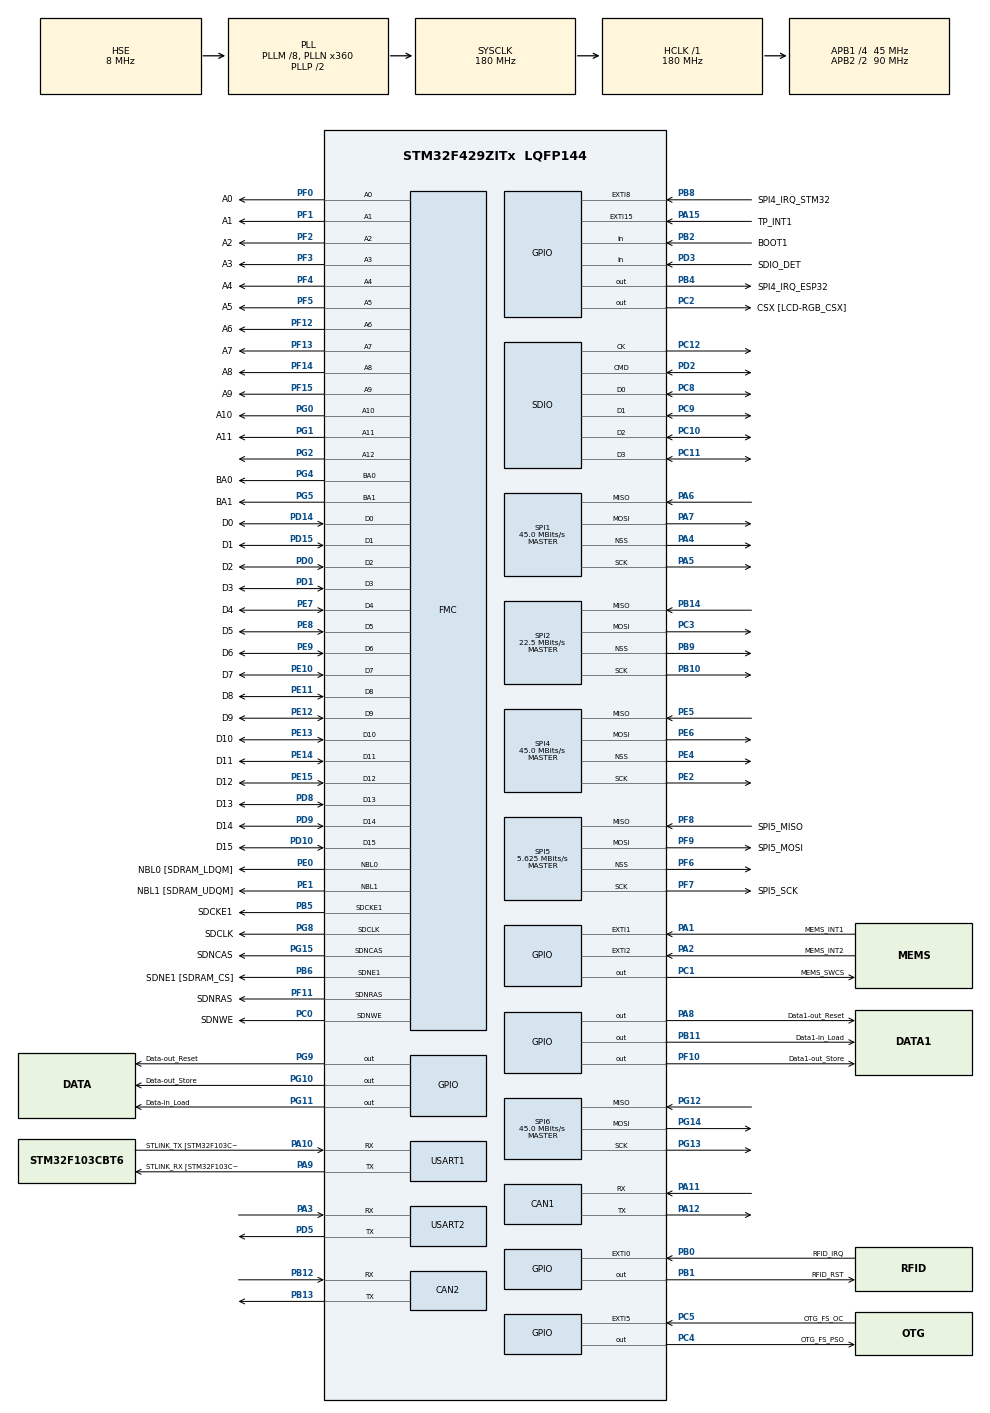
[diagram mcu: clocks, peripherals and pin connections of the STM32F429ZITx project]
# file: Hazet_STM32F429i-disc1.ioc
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CAN1.BS1=CAN_BS1_1TQ
CAN1.BS2=CAN_BS2_1TQ
CAN1.CalculateTimeQuantum=355.55555555555554
CAN2.BS1=CAN_BS1_1TQ
CAN2.BS2=CAN_BS2_1TQ
CAN2.CalculateTimeQuantum=355.55555555555554
Dma.Request0=SPI5_TX
Dma.Request1=USART2_TX
Dma.Request2=SDIO_RX
Dma.Request3=SDIO_TX
Dma.SDIO_RX.2.Direction=DMA_PERIPH_TO_MEMORY
Dma.SDIO_RX.2.FIFOMode=DMA_FIFOMODE_ENABLE
Dma.SDIO_RX.2.FIFOThreshold=DMA_FIFO_THRESHOLD_FULL
Dma.SDIO_RX.2.Instance=DMA2_Stream3
Dma.SDIO_RX.2.MemBurst=DMA_MBURST_INC4
Dma.SDIO_RX.2.MemDataAlignment=DMA_MDATAALIGN_WORD
Dma.SDIO_RX.2.MemInc=DMA_MINC_ENABLE
Dma.SDIO_RX.2.Mode=DMA_PFCTRL
Dma.SDIO_RX.2.PeriphBurst=DMA_PBURST_INC4
Dma.SDIO_RX.2.PeriphDataAlignment=DMA_PDATAALIGN_WORD
Dma.SDIO_RX.2.PeriphInc=DMA_PINC_DISABLE
Dma.SDIO_RX.2.Priority=DMA_PRIORITY_LOW
Dma.SDIO_TX.3.Direction=DMA_MEMORY_TO_PERIPH
Dma.SDIO_TX.3.FIFOMode=DMA_FIFOMODE_ENABLE
Dma.SDIO_TX.3.FIFOThreshold=DMA_FIFO_THRESHOLD_FULL
Dma.SDIO_TX.3.Instance=DMA2_Stream6
Dma.SDIO_TX.3.MemBurst=DMA_MBURST_INC4
Dma.SDIO_TX.3.MemDataAlignment=DMA_MDATAALIGN_WORD
Dma.SDIO_TX.3.MemInc=DMA_MINC_ENABLE
Dma.SDIO_TX.3.Mode=DMA_PFCTRL
Dma.SDIO_TX.3.PeriphBurst=DMA_PBURST_INC4
Dma.SDIO_TX.3.PeriphDataAlignment=DMA_PDATAALIGN_WORD
Dma.SDIO_TX.3.PeriphInc=DMA_PINC_DISABLE
Dma.SDIO_TX.3.Priority=DMA_PRIORITY_LOW
Dma.SPI5_TX.0.Direction=DMA_MEMORY_TO_PERIPH
Dma.SPI5_TX.0.FIFOMode=DMA_FIFOMODE_DISABLE
Dma.SPI5_TX.0.Instance=DMA2_Stream4
Dma.SPI5_TX.0.MemDataAlignment=DMA_MDATAALIGN_BYTE
Dma.SPI5_TX.0.MemInc=DMA_MINC_ENABLE
Dma.SPI5_TX.0.Mode=DMA_NORMAL
Dma.SPI5_TX.0.PeriphDataAlignment=DMA_PDATAALIGN_BYTE
Dma.SPI5_TX.0.PeriphInc=DMA_PINC_DISABLE
Dma.SPI5_TX.0.Priority=DMA_PRIORITY_LOW
Dma.USART2_TX.1.Direction=DMA_MEMORY_TO_PERIPH
Dma.USART2_TX.1.FIFOMode=DMA_FIFOMODE_DISABLE
Dma.USART2_TX.1.Instance=DMA1_Stream6
Dma.USART2_TX.1.MemDataAlignment=DMA_MDATAALIGN_BYTE
Dma.USART2_TX.1.MemInc=DMA_MINC_ENABLE
Dma.USART2_TX.1.Mode=DMA_NORMAL
Dma.USART2_TX.1.PeriphDataAlignment=DMA_PDATAALIGN_BYTE
Dma.USART2_TX.1.PeriphInc=DMA_PINC_DISABLE
Dma.USART2_TX.1.Priority=DMA_PRIORITY_LOW
FATFS.BSP.number=1
FATFS.USE_DMA_CODE_SD=1
FATFS0.BSP.STBoard=false
FATFS0.BSP.api=Unknown
FATFS0.BSP.i2caddr=0
FATFS0.BSP.instance=PD3
FATFS0.BSP.ip=GPIO
FATFS0.BSP.mode=Input
FATFS0.BSP.name=Detect_SDIO
FATFS0.BSP.solution=PD3
FMC.CASLatency1=FMC_SDRAM_CAS_LATENCY_3
FMC.ExitSelfRefreshDelay1=7
FMC.LoadToActiveDelay1=2
FMC.RCDDelay1=2
FMC.RPDelay1=2
FMC.ReadBurst1=FMC_SDRAM_RBURST_DISABLE
FMC.ReadPipeDelay1=FMC_SDRAM_RPIPE_DELAY_1
FMC.RowCycleDelay1=7
FMC.SDClockPeriod1=FMC_SDRAM_CLOCK_PERIOD_2
FMC.SelfRefreshTime1=4
FMC.WriteRecoveryTime1=3
Mcu.Family=STM32F4
Mcu.Name=STM32F429ZITx
Mcu.Package=LQFP144
NVIC.DMA1_Stream6_IRQn=true\:0\:0\:false\:false\:true\:false\:true
NVIC.DMA2_Stream3_IRQn=true\:0\:0\:false\:false\:true\:false\:true
NVIC.DMA2_Stream4_IRQn=true\:0\:0\:false\:false\:true\:false\:true
NVIC.DMA2_Stream6_IRQn=true\:0\:0\:false\:false\:true\:false\:true
NVIC.PriorityGroup=NVIC_PRIORITYGROUP_4
NVIC.SDIO_IRQn=true\:0\:0\:false\:false\:true\:true\:true
NVIC.SPI5_IRQn=true\:0\:0\:false\:false\:true\:true\:true
NVIC.TIM6_DAC_IRQn=true\:0\:0\:false\:false\:true\:false\:true
NVIC.TimeBase=TIM6_DAC_IRQn
NVIC.TimeBaseIP=TIM6
NVIC.USART2_IRQn=true\:0\:0\:false\:false\:true\:true\:true
PA1.GPIO_Label=MEMS_INT1
PA1.GPIO_ModeDefaultEXTI=GPIO_MODE_EVT_RISING
PA1.GPIO_PuPd=GPIO_NOPULL
PA1.Signal=GPXTI1
PA10.GPIO_Label=STLINK_TX [STM32F103CBT6_PA2]
PA10.Mode=Asynchronous
PA10.Signal=USART1_RX
PA11.Mode=Master
PA11.Signal=CAN1_RX
PA12.Mode=Master
PA12.Signal=CAN1_TX
PA13.GPIO_Label=SWDIO
PA13.Mode=Trace_Asynchronous_SW
PA13.Signal=SYS_JTMS-SWDIO
PA14.GPIO_Label=SWCLK
PA14.Mode=Trace_Asynchronous_SW
PA14.Signal=SYS_JTCK-SWCLK
PA15.GPIO_Label=TP_INT1
PA15.GPIO_ModeDefaultEXTI=GPIO_MODE_EVT_RISING
PA15.GPIO_PuPd=GPIO_NOPULL
PA15.Signal=GPXTI15
PA2.GPIO_Label=MEMS_INT2
PA2.GPIO_ModeDefaultEXTI=GPIO_MODE_EVT_RISING
PA2.GPIO_PuPd=GPIO_NOPULL
PA2.Signal=GPXTI2
PA3.Mode=Asynchronous
PA3.Signal=USART2_RX
PA4.Mode=NSS_Signal_Hard_Output
PA4.Signal=SPI1_NSS
PA5.Mode=Full_Duplex_Master
PA5.Signal=SPI1_SCK
PA6.Mode=Full_Duplex_Master
PA6.Signal=SPI1_MISO
PA7.Mode=Full_Duplex_Master
PA7.Signal=SPI1_MOSI
PA8.GPIO_Label=Data1-out_Reset
PA8.Signal=GPIO_Output
PA9.GPIO_Label=STLINK_RX [STM32F103CBT6_PA3]
PA9.Mode=Asynchronous
PA9.Signal=USART1_TX
PB0.GPIO_Label=RFID_IRQ
PB0.Signal=GPXTI0
PB1.GPIO_Label=RFID_RST
PB1.Signal=GPIO_Output
PB10.Mode=Full_Duplex_Master
PB10.Signal=SPI2_SCK
PB11.GPIO_Label=Data1-in_Load
PB11.Signal=GPIO_Output
PB12.Mode=Slave
PB12.Signal=CAN2_RX
PB13.Mode=Slave
PB13.Signal=CAN2_TX
PB14.Mode=Full_Duplex_Master
PB14.Signal=SPI2_MISO
PB2/BOOT1.GPIO_Label=BOOT1
PB2/BOOT1.GPIO_Mode=GPIO_MODE_INPUT
PB2/BOOT1.GPIO_PuPd=GPIO_NOPULL
PB2/BOOT1.Signal=GPIO_Input
PB3.GPIO_Label=SWO
PB3.Mode=Trace_Asynchronous_SW
PB3.Signal=SYS_JTDO-SWO
PB4.GPIO_Label=SPI4_IRQ_ESP32
PB4.Signal=GPIO_Output
PB5.GPIO_Label=SDCKE1
PB5.GPIO_Mode=GPIO_MODE_AF_PP
PB5.GPIO_PuPd=GPIO_NOPULL
PB5.GPIO_Speed=GPIO_SPEED_FREQ_VERY_HIGH
PB5.Mode=SdramChipSelect2_1
PB5.Signal=FMC_SDCKE1
PB6.GPIO_Label=SDNE1 [SDRAM_CS]
PB6.GPIO_Mode=GPIO_MODE_AF_PP
PB6.GPIO_PuPd=GPIO_NOPULL
PB6.GPIO_Speed=GPIO_SPEED_FREQ_VERY_HIGH
PB6.Mode=SdramChipSelect2_1
PB6.Signal=FMC_SDNE1
PB8.GPIO_Label=SPI4_IRQ_STM32
PB8.Signal=GPXTI8
PB9.Mode=NSS_Signal_Hard_Output
PB9.Signal=SPI2_NSS
PC0.GPIO_Label=SDNWE
PC0.GPIO_Mode=GPIO_MODE_AF_PP
PC0.GPIO_PuPd=GPIO_NOPULL
PC0.GPIO_Speed=GPIO_SPEED_FREQ_VERY_HIGH
PC0.Signal=FMC_SDNWE
PC1.GPIO_Label=MEMS_SWCS
PC1.GPIO_Mode=GPIO_MODE_OUTPUT_PP
PC1.GPIO_PuPd=GPIO_NOPULL
PC1.GPIO_Speed=GPIO_SPEED_FREQ_LOW
PC1.Signal=GPIO_Output
PC10.Mode=SD_4_bits_Wide_bus
PC10.Signal=SDIO_D2
PC11.Mode=SD_4_bits_Wide_bus
PC11.Signal=SDIO_D3
PC12.Mode=SD_4_bits_Wide_bus
PC12.Signal=SDIO_CK
PC2.GPIO_Label=CSX [LCD-RGB_CSX]
PC2.GPIO_Mode=GPIO_MODE_OUTPUT_PP
PC2.GPIO_PuPd=GPIO_NOPULL
PC2.GPIO_Speed=GPIO_SPEED_FREQ_LOW
PC2.Signal=GPIO_Output
PC3.Mode=Full_Duplex_Master
PC3.Signal=SPI2_MOSI
PC4.GPIO_Label=OTG_FS_PSO
PC4.GPIO_Mode=GPIO_MODE_OUTPUT_PP
PC4.GPIO_PuPd=GPIO_NOPULL
PC4.GPIO_Speed=GPIO_SPEED_FREQ_LOW
PC4.Signal=GPIO_Output
PC5.GPIO_Label=OTG_FS_OC
PC5.GPIO_ModeDefaultEXTI=GPIO_MODE_EVT_RISING
PC5.Signal=GPXTI5
PC8.Mode=SD_4_bits_Wide_bus
PC8.Signal=SDIO_D0
PC9.Mode=SD_4_bits_Wide_bus
PC9.Signal=SDIO_D1
PD0.GPIO_Label=D2
PD0.GPIO_Mode=GPIO_MODE_AF_PP
PD0.GPIO_PuPd=GPIO_NOPULL
PD0.GPIO_Speed=GPIO_SPEED_FREQ_VERY_HIGH
PD0.Signal=FMC_D2_DA2
PD1.GPIO_Label=D3
PD1.GPIO_Mode=GPIO_MODE_AF_PP
PD1.GPIO_PuPd=GPIO_NOPULL
PD1.GPIO_Speed=GPIO_SPEED_FREQ_VERY_HIGH
PD1.Signal=FMC_D3_DA3
PD10.GPIO_Label=D15
PD10.GPIO_Mode=GPIO_MODE_AF_PP
PD10.GPIO_PuPd=GPIO_NOPULL
PD10.GPIO_Speed=GPIO_SPEED_FREQ_VERY_HIGH
PD10.Signal=FMC_D15_DA15
PD14.GPIO_Label=D0
PD14.GPIO_Mode=GPIO_MODE_AF_PP
PD14.GPIO_PuPd=GPIO_NOPULL
PD14.GPIO_Speed=GPIO_SPEED_FREQ_VERY_HIGH
PD14.Signal=FMC_D0_DA0
PD15.GPIO_Label=D1
PD15.GPIO_Mode=GPIO_MODE_AF_PP
PD15.GPIO_PuPd=GPIO_NOPULL
PD15.GPIO_Speed=GPIO_SPEED_FREQ_VERY_HIGH
PD15.Signal=FMC_D1_DA1
PD2.Mode=SD_4_bits_Wide_bus
PD2.Signal=SDIO_CMD
PD3.GPIO_Label=SDIO_DET
PD3.Signal=GPIO_Input
PD5.Mode=Asynchronous
PD5.Signal=USART2_TX
PD8.GPIO_Label=D13
PD8.GPIO_Mode=GPIO_MODE_AF_PP
PD8.GPIO_PuPd=GPIO_NOPULL
PD8.GPIO_Speed=GPIO_SPEED_FREQ_VERY_HIGH
PD8.Signal=FMC_D13_DA13
PD9.GPIO_Label=D14
PD9.GPIO_Mode=GPIO_MODE_AF_PP
PD9.GPIO_PuPd=GPIO_NOPULL
PD9.GPIO_Speed=GPIO_SPEED_FREQ_VERY_HIGH
PD9.Signal=FMC_D14_DA14
PE0.GPIO_Label=NBL0 [SDRAM_LDQM]
PE0.GPIO_Mode=GPIO_MODE_AF_PP
PE0.GPIO_PuPd=GPIO_NOPULL
PE0.GPIO_Speed=GPIO_SPEED_FREQ_VERY_HIGH
PE0.Signal=FMC_NBL0
PE1.GPIO_Label=NBL1 [SDRAM_UDQM]
PE1.GPIO_Mode=GPIO_MODE_AF_PP
PE1.GPIO_PuPd=GPIO_NOPULL
PE1.GPIO_Speed=GPIO_SPEED_FREQ_VERY_HIGH
PE1.Signal=FMC_NBL1
PE10.GPIO_Label=D7
PE10.GPIO_Mode=GPIO_MODE_AF_PP
PE10.GPIO_PuPd=GPIO_NOPULL
PE10.GPIO_Speed=GPIO_SPEED_FREQ_VERY_HIGH
PE10.Signal=FMC_D7_DA7
PE11.GPIO_Label=D8
PE11.GPIO_Mode=GPIO_MODE_AF_PP
PE11.GPIO_PuPd=GPIO_NOPULL
PE11.GPIO_Speed=GPIO_SPEED_FREQ_VERY_HIGH
PE11.Signal=FMC_D8_DA8
PE12.GPIO_Label=D9
PE12.GPIO_Mode=GPIO_MODE_AF_PP
PE12.GPIO_PuPd=GPIO_NOPULL
PE12.GPIO_Speed=GPIO_SPEED_FREQ_VERY_HIGH
PE12.Signal=FMC_D9_DA9
PE13.GPIO_Label=D10
PE13.GPIO_Mode=GPIO_MODE_AF_PP
PE13.GPIO_PuPd=GPIO_NOPULL
PE13.GPIO_Speed=GPIO_SPEED_FREQ_VERY_HIGH
PE13.Signal=FMC_D10_DA10
PE14.GPIO_Label=D11
PE14.GPIO_Mode=GPIO_MODE_AF_PP
PE14.GPIO_PuPd=GPIO_NOPULL
PE14.GPIO_Speed=GPIO_SPEED_FREQ_VERY_HIGH
PE14.Signal=FMC_D11_DA11
PE15.GPIO_Label=D12
PE15.GPIO_Mode=GPIO_MODE_AF_PP
PE15.GPIO_PuPd=GPIO_NOPULL
PE15.GPIO_Speed=GPIO_SPEED_FREQ_VERY_HIGH
PE15.Signal=FMC_D12_DA12
PE2.Mode=Full_Duplex_Master
PE2.Signal=SPI4_SCK
PE4.Mode=NSS_Signal_Hard_Output
PE4.Signal=SPI4_NSS
PE5.Mode=Full_Duplex_Master
PE5.Signal=SPI4_MISO
PE6.Mode=Full_Duplex_Master
PE6.Signal=SPI4_MOSI
PE7.GPIO_Label=D4
PE7.GPIO_Mode=GPIO_MODE_AF_PP
PE7.GPIO_PuPd=GPIO_NOPULL
PE7.GPIO_Speed=GPIO_SPEED_FREQ_VERY_HIGH
PE7.Signal=FMC_D4_DA4
PE8.GPIO_Label=D5
PE8.GPIO_Mode=GPIO_MODE_AF_PP
PE8.GPIO_PuPd=GPIO_NOPULL
PE8.GPIO_Speed=GPIO_SPEED_FREQ_VERY_HIGH
PE8.Signal=FMC_D5_DA5
PE9.GPIO_Label=D6
PE9.GPIO_Mode=GPIO_MODE_AF_PP
PE9.GPIO_PuPd=GPIO_NOPULL
PE9.GPIO_Speed=GPIO_SPEED_FREQ_VERY_HIGH
PE9.Signal=FMC_D6_DA6
PF0.GPIO_Label=A0
PF0.GPIO_Mode=GPIO_MODE_AF_PP
PF0.GPIO_PuPd=GPIO_NOPULL
PF0.GPIO_Speed=GPIO_SPEED_FREQ_VERY_HIGH
PF0.Signal=FMC_A0
PF1.GPIO_Label=A1
PF1.GPIO_Mode=GPIO_MODE_AF_PP
PF1.GPIO_PuPd=GPIO_NOPULL
PF1.GPIO_Speed=GPIO_SPEED_FREQ_VERY_HIGH
PF1.Signal=FMC_A1
PF10.GPIO_Label=Data1-out_Store
PF10.Signal=GPIO_Output
PF11.GPIO_Label=SDNRAS
PF11.GPIO_Mode=GPIO_MODE_AF_PP
PF11.GPIO_PuPd=GPIO_NOPULL
PF11.GPIO_Speed=GPIO_SPEED_FREQ_VERY_HIGH
PF11.Signal=FMC_SDNRAS
PF12.GPIO_Label=A6
PF12.GPIO_Mode=GPIO_MODE_AF_PP
PF12.GPIO_PuPd=GPIO_NOPULL
PF12.GPIO_Speed=GPIO_SPEED_FREQ_VERY_HIGH
PF12.Signal=FMC_A6
PF13.GPIO_Label=A7
PF13.GPIO_Mode=GPIO_MODE_AF_PP
PF13.GPIO_PuPd=GPIO_NOPULL
PF13.GPIO_Speed=GPIO_SPEED_FREQ_VERY_HIGH
PF13.Signal=FMC_A7
PF14.GPIO_Label=A8
PF14.GPIO_Mode=GPIO_MODE_AF_PP
PF14.GPIO_PuPd=GPIO_NOPULL
PF14.GPIO_Speed=GPIO_SPEED_FREQ_VERY_HIGH
PF14.Signal=FMC_A8
PF15.GPIO_Label=A9
PF15.GPIO_Mode=GPIO_MODE_AF_PP
PF15.GPIO_PuPd=GPIO_NOPULL
PF15.GPIO_Speed=GPIO_SPEED_FREQ_VERY_HIGH
PF15.Signal=FMC_A9
PF2.GPIO_Label=A2
PF2.GPIO_Mode=GPIO_MODE_AF_PP
PF2.GPIO_PuPd=GPIO_NOPULL
PF2.GPIO_Speed=GPIO_SPEED_FREQ_VERY_HIGH
PF2.Signal=FMC_A2
PF3.GPIO_Label=A3
PF3.GPIO_Mode=GPIO_MODE_AF_PP
PF3.GPIO_PuPd=GPIO_NOPULL
PF3.GPIO_Speed=GPIO_SPEED_FREQ_VERY_HIGH
PF3.Signal=FMC_A3
PF4.GPIO_Label=A4
PF4.GPIO_Mode=GPIO_MODE_AF_PP
PF4.GPIO_PuPd=GPIO_NOPULL
PF4.GPIO_Speed=GPIO_SPEED_FREQ_VERY_HIGH
PF4.Signal=FMC_A4
PF5.GPIO_Label=A5
PF5.GPIO_Mode=GPIO_MODE_AF_PP
PF5.GPIO_PuPd=GPIO_NOPULL
PF5.GPIO_Speed=GPIO_SPEED_FREQ_VERY_HIGH
PF5.Signal=FMC_A5
PF6.Mode=NSS_Signal_Hard_Output
PF6.Signal=SPI5_NSS
PF7.GPIO_Label=SPI5_SCK
PF7.GPIO_Mode=GPIO_MODE_AF_PP
PF7.GPIO_PuPd=GPIO_NOPULL
PF7.GPIO_Speed=GPIO_SPEED_FREQ_LOW
PF7.Mode=Full_Duplex_Master
PF7.Signal=SPI5_SCK
PF8.GPIO_Label=SPI5_MISO
PF8.GPIO_Mode=GPIO_MODE_AF_PP
PF8.GPIO_PuPd=GPIO_NOPULL
PF8.GPIO_Speed=GPIO_SPEED_FREQ_LOW
PF8.Mode=Full_Duplex_Master
PF8.Signal=SPI5_MISO
PF9.GPIO_Label=SPI5_MOSI
PF9.GPIO_Mode=GPIO_MODE_AF_PP
PF9.GPIO_PuPd=GPIO_NOPULL
PF9.GPIO_Speed=GPIO_SPEED_FREQ_LOW
PF9.Mode=Full_Duplex_Master
PF9.Signal=SPI5_MOSI
PG0.GPIO_Label=A10
PG0.GPIO_Mode=GPIO_MODE_AF_PP
PG0.GPIO_PuPd=GPIO_NOPULL
PG0.GPIO_Speed=GPIO_SPEED_FREQ_VERY_HIGH
PG0.Signal=FMC_A10
PG1.GPIO_Label=A11
PG1.GPIO_Mode=GPIO_MODE_AF_PP
PG1.GPIO_PuPd=GPIO_NOPULL
PG1.GPIO_Speed=GPIO_SPEED_FREQ_VERY_HIGH
PG1.Signal=FMC_A11
PG10.GPIO_Label=Data-out_Store
PG10.Signal=GPIO_Output
PG11.GPIO_Label=Data-in_Load
PG11.Signal=GPIO_Output
PG12.Mode=Full_Duplex_Master
PG12.Signal=SPI6_MISO
PG13.Mode=Full_Duplex_Master
PG13.Signal=SPI6_SCK
PG14.Mode=Full_Duplex_Master
PG14.Signal=SPI6_MOSI
PG15.GPIO_Label=SDNCAS
PG15.GPIO_Mode=GPIO_MODE_AF_PP
PG15.GPIO_PuPd=GPIO_NOPULL
PG15.GPIO_Speed=GPIO_SPEED_FREQ_VERY_HIGH
PG15.Signal=FMC_SDNCAS
PG2.Signal=FMC_A12
PG4.GPIO_Label=BA0
PG4.GPIO_Mode=GPIO_MODE_AF_PP
PG4.GPIO_PuPd=GPIO_NOPULL
PG4.GPIO_Speed=GPIO_SPEED_FREQ_VERY_HIGH
PG4.Signal=FMC_A14_BA0
PG5.GPIO_Label=BA1
PG5.GPIO_Mode=GPIO_MODE_AF_PP
PG5.GPIO_PuPd=GPIO_NOPULL
PG5.GPIO_Speed=GPIO_SPEED_FREQ_VERY_HIGH
PG5.Signal=FMC_A15_BA1
PG8.GPIO_Label=SDCLK
PG8.GPIO_Mode=GPIO_MODE_AF_PP
PG8.GPIO_PuPd=GPIO_NOPULL
PG8.GPIO_Speed=GPIO_SPEED_FREQ_VERY_HIGH
PG8.Signal=FMC_SDCLK
PG9.GPIO_Label=Data-out_Reset
PG9.Signal=GPIO_Output
PH0/OSC_IN.GPIO_Label=PH0-OSC_IN
PH0/OSC_IN.Mode=HSE-External-Oscillator
PH0/OSC_IN.Signal=RCC_OSC_IN
PH1/OSC_OUT.GPIO_Label=PH1-OSC_OUT
PH1/OSC_OUT.Mode=HSE-External-Oscillator
PH1/OSC_OUT.Signal=RCC_OSC_OUT
ProjectManager.HeapSize=0x800
ProjectManager.StackSize=0x1000
ProjectManager.TargetToolchain=SW4STM32
RCC.48MHZClocksFreq_Value=45000000
RCC.AHBFreq_Value=180000000
RCC.APB1CLKDivider=RCC_HCLK_DIV4
RCC.APB1Freq_Value=45000000
RCC.APB1TimFreq_Value=90000000
RCC.APB2CLKDivider=RCC_HCLK_DIV2
RCC.APB2Freq_Value=90000000
RCC.APB2TimFreq_Value=180000000
RCC.CortexFreq_Value=180000000
RCC.HCLKFreq_Value=180000000
RCC.HSE_VALUE=8000000
RCC.HSI_VALUE=16000000
RCC.PLLM=8
RCC.PLLN=360
RCC.PLLQ=8
RCC.PLLSAIN=50
RCC.PLLSourceVirtual=RCC_PLLSOURCE_HSE
RCC.SYSCLKFreq_VALUE=180000000
RCC.SYSCLKSource=RCC_SYSCLKSOURCE_PLLCLK
RCC.VCOOutputFreq_Value=360000000
SH.FMC_A0.0=FMC_A0,13b-sda1
SH.FMC_A1.0=FMC_A1,13b-sda1
SH.FMC_A10.0=FMC_A10,13b-sda1
SH.FMC_A11.0=FMC_A11,13b-sda1
SH.FMC_A12.0=FMC_A12,13b-sda1
SH.FMC_A14_BA0.0=FMC_BA0,FourSdramBanks1
SH.FMC_A15_BA1.0=FMC_BA1,FourSdramBanks1
SH.FMC_A2.0=FMC_A2,13b-sda1
SH.FMC_A3.0=FMC_A3,13b-sda1
SH.FMC_A4.0=FMC_A4,13b-sda1
SH.FMC_A5.0=FMC_A5,13b-sda1
SH.FMC_A6.0=FMC_A6,13b-sda1
SH.FMC_A7.0=FMC_A7,13b-sda1
SH.FMC_A8.0=FMC_A8,13b-sda1
SH.FMC_A9.0=FMC_A9,13b-sda1
SH.FMC_D0_DA0.0=FMC_D0,sd-16b-d1
SH.FMC_D10_DA10.0=FMC_D10,sd-16b-d1
SH.FMC_D11_DA11.0=FMC_D11,sd-16b-d1
SH.FMC_D12_DA12.0=FMC_D12,sd-16b-d1
SH.FMC_D13_DA13.0=FMC_D13,sd-16b-d1
SH.FMC_D14_DA14.0=FMC_D14,sd-16b-d1
SH.FMC_D15_DA15.0=FMC_D15,sd-16b-d1
SH.FMC_D1_DA1.0=FMC_D1,sd-16b-d1
SH.FMC_D2_DA2.0=FMC_D2,sd-16b-d1
SH.FMC_D3_DA3.0=FMC_D3,sd-16b-d1
SH.FMC_D4_DA4.0=FMC_D4,sd-16b-d1
SH.FMC_D5_DA5.0=FMC_D5,sd-16b-d1
SH.FMC_D6_DA6.0=FMC_D6,sd-16b-d1
SH.FMC_D7_DA7.0=FMC_D7,sd-16b-d1
SH.FMC_D8_DA8.0=FMC_D8,sd-16b-d1
SH.FMC_D9_DA9.0=FMC_D9,sd-16b-d1
SH.FMC_NBL0.0=FMC_NBL0,Sd2ByteEnable1
SH.FMC_NBL1.0=FMC_NBL1,Sd2ByteEnable1
SH.FMC_SDCLK.0=FMC_SDCLK,13b-sda1
SH.FMC_SDNCAS.0=FMC_SDNCAS,13b-sda1
SH.FMC_SDNRAS.0=FMC_SDNRAS,13b-sda1
SH.FMC_SDNWE.0=FMC_SDNWE,13b-sda1
SPI1.BaudRatePrescaler=SPI_BAUDRATEPRESCALER_2
SPI1.CalculateBaudRate=45.0 MBits/s
SPI1.Direction=SPI_DIRECTION_2LINES
SPI1.Mode=SPI_MODE_MASTER
SPI1.VirtualNSS=VM_NSSHARD
SPI1.VirtualType=VM_MASTER
SPI2.BaudRatePrescaler=SPI_BAUDRATEPRESCALER_2
SPI2.CalculateBaudRate=22.5 MBits/s
SPI2.Direction=SPI_DIRECTION_2LINES
SPI2.Mode=SPI_MODE_MASTER
SPI2.VirtualNSS=VM_NSSHARD
SPI2.VirtualType=VM_MASTER
SPI4.BaudRatePrescaler=SPI_BAUDRATEPRESCALER_2
SPI4.CalculateBaudRate=45.0 MBits/s
SPI4.Direction=SPI_DIRECTION_2LINES
SPI4.Mode=SPI_MODE_MASTER
SPI4.VirtualNSS=VM_NSSHARD
SPI4.VirtualType=VM_MASTER
SPI5.BaudRatePrescaler=SPI_BAUDRATEPRESCALER_16
SPI5.CalculateBaudRate=5.625 MBits/s
SPI5.Direction=SPI_DIRECTION_2LINES
SPI5.Mode=SPI_MODE_MASTER
SPI5.VirtualNSS=VM_NSSHARD
SPI5.VirtualType=VM_MASTER
SPI6.BaudRatePrescaler=SPI_BAUDRATEPRESCALER_2
SPI6.CalculateBaudRate=45.0 MBits/s
SPI6.Direction=SPI_DIRECTION_2LINES
SPI6.Mode=SPI_MODE_MASTER
SPI6.VirtualType=VM_MASTER
USART1.VirtualMode=VM_ASYNC
USART2.VirtualMode=VM_ASYNC
VP_CRC_VS_CRC.Mode=CRC_Activate
VP_FATFS_VS_SDIO.Mode=SDIO
VP_SYS_VS_tim6.Mode=TIM6
VP_TIM1_VS_ClockSourceINT.Mode=Internal
board=STM32F429I-DISC1

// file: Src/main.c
/* USER CODE BEGIN Header */
/**
  ******************************************************************************
  * @file           : main.c
  * @brief          : Main program body
  ******************************************************************************
  * @attention
  *
  * <h2><center>&copy; Copyright (c) 2019 STMicroelectronics.
  * All rights reserved.</center></h2>
  *
  * This software component is licensed by ST under Ultimate Liberty license
  * SLA0044, the "License"; You may not use this file except in compliance with
  * the License. You may obtain a copy of the License at:
  *                             www.st.com/SLA0044
  *
  ******************************************************************************
  */
/* USER CODE END Header */

#include "main.h"
#include "can.h"
#include "crc.h"
#include "dma.h"
#include "fatfs.h"
#include "sdio.h"
#include "spi.h"
#include "tim.h"
#include "usart.h"
#include "gpio.h"
#include "fmc.h"

/* USER CODE BEGIN Includes */
#include "MFRC522_SPI.h"
/* USER CODE END Includes */

/* USER CODE BEGIN PV */
uint8_t meldung01[] = "Hallo Hazet !\r\n";
uint8_t *ptr_meldung01 = &meldung01[0];

uint8_t ESP01_RX_buf[1] = " ";
uint8_t *ptr_ESP01_RX_buf = &ESP01_RX_buf[0];

uint8_t AT_cmd00[] = "AT\r\n";
uint16_t AT_cmd00size = 4;
uint8_t *ptr_ATcmd00 = &AT_cmd00[0];

uint8_t AT_cmd01[] = "AT+GMR\r\n";
uint16_t AT_cmd01size = 8;
uint8_t *ptr_ATcmd01 = &AT_cmd01[0];

uint8_t AT_cmd02[] = "AT+CWMODE_CUR=1\r\n";
uint16_t AT_cmd02size = 17;
uint8_t *ptr_ATcmd02 = &AT_cmd02[0];

uint8_t AT_cmd03[] = "AT+CWLAP\r\n";
uint16_t AT_cmd03size = 10;
uint8_t *ptr_ATcmd03 = &AT_cmd03[0];
/* USER CODE END PV */

void SystemClock_Config(void);

/* USER CODE BEGIN 0 */
void HAL_UART_RxCpltCallback(UART_HandleTypeDef *huart)
{
  /* Prevent unused argument(s) compilation warning */
  UNUSED(huart);
  /* NOTE: This function should not be modified, when the callback is needed,
           the HAL_UART_RxCpltCallback could be implemented in the user file
   */
	//if (huart == &huart2) {
		HAL_UART_Transmit(&huart1, ptr_ESP01_RX_buf, 1, 1);
		HAL_UART_Receive_IT(&huart2, ptr_ESP01_RX_buf, 1);
	//}
}
void HAL_UART_TxCpltCallback(UART_HandleTypeDef *huart)
{
  /* Prevent unused argument(s) compilation warning */
  UNUSED(huart);
  /* NOTE: This function should not be modified, when the callback is needed,
           the HAL_UART_TxCpltCallback could be implemented in the user file
   */
	if (huart == &huart1) {
		//HAL_UART_Receive_IT(&huart2, ptr_ESP01_RX_buf, 1);
	}
}
/* USER CODE END 0 */

int main(void)
{

  /* MCU Configuration--------------------------------------------------------*/

  /* Reset of all peripherals, Initializes the Flash interface and the Systick. */
  HAL_Init();

  /* Configure the system clock */
  SystemClock_Config();

  /* Initialize all configured peripherals */
  MX_GPIO_Init();
  MX_DMA_Init();
  MX_CAN1_Init();
  MX_CAN2_Init();
  MX_CRC_Init();
  MX_FMC_Init();
  MX_SDIO_SD_Init();
  MX_SPI1_Init();
  MX_SPI2_Init();
  MX_SPI4_Init();
  MX_SPI5_Init();
  MX_SPI6_Init();
  MX_TIM1_Init();
  MX_USART1_UART_Init();
  MX_USART2_UART_Init();
  MX_FATFS_Init();
  /* USER CODE BEGIN 2 */
  HAL_UART_Receive_IT(&huart2, ptr_ESP01_RX_buf, 1);
  /* USER CODE END 2 */

  /* Infinite loop */
  while (1)
  {

    /* USER CODE BEGIN 3 */
	  HAL_UART_Transmit(&huart2, ptr_ATcmd00, AT_cmd00size, 10);
	  HAL_Delay(1000);
	  HAL_UART_Transmit(&huart2, ptr_ATcmd01, AT_cmd01size, 100);
	  HAL_Delay(3000);
	  HAL_UART_Transmit(&huart2, ptr_ATcmd02, AT_cmd02size, 100);
	  HAL_Delay(3000);
	  HAL_UART_Transmit(&huart2, ptr_ATcmd03, AT_cmd03size, 100);
	  HAL_Delay(10000);
  }
  /* USER CODE END 3 */
}

void SystemClock_Config(void)
{
  RCC_OscInitTypeDef RCC_OscInitStruct = {0};
  RCC_ClkInitTypeDef RCC_ClkInitStruct = {0};

  /** Configure the main internal regulator output voltage
  */
  __HAL_RCC_PWR_CLK_ENABLE();
  __HAL_PWR_VOLTAGESCALING_CONFIG(PWR_REGULATOR_VOLTAGE_SCALE1);
  /** Initializes the CPU, AHB and APB busses clocks
  */
  RCC_OscInitStruct.OscillatorType = RCC_OSCILLATORTYPE_HSE;
  RCC_OscInitStruct.HSEState = RCC_HSE_ON;
  RCC_OscInitStruct.PLL.PLLState = RCC_PLL_ON;
  RCC_OscInitStruct.PLL.PLLSource = RCC_PLLSOURCE_HSE;
  RCC_OscInitStruct.PLL.PLLM = 8;
  RCC_OscInitStruct.PLL.PLLN = 360;
  RCC_OscInitStruct.PLL.PLLP = RCC_PLLP_DIV2;
  RCC_OscInitStruct.PLL.PLLQ = 8;
  if (HAL_RCC_OscConfig(&RCC_OscInitStruct) != HAL_OK)
  {
    Error_Handler();
  }
  /** Activate the Over-Drive mode
  */
  if (HAL_PWREx_EnableOverDrive() != HAL_OK)
  {
    Error_Handler();
  }
  /** Initializes the CPU, AHB and APB busses clocks
  */
  RCC_ClkInitStruct.ClockType = RCC_CLOCKTYPE_HCLK|RCC_CLOCKTYPE_SYSCLK
                              |RCC_CLOCKTYPE_PCLK1|RCC_CLOCKTYPE_PCLK2;
  RCC_ClkInitStruct.SYSCLKSource = RCC_SYSCLKSOURCE_PLLCLK;
  RCC_ClkInitStruct.AHBCLKDivider = RCC_SYSCLK_DIV1;
  RCC_ClkInitStruct.APB1CLKDivider = RCC_HCLK_DIV4;
  RCC_ClkInitStruct.APB2CLKDivider = RCC_HCLK_DIV2;

  if (HAL_RCC_ClockConfig(&RCC_ClkInitStruct, FLASH_LATENCY_5) != HAL_OK)
  {
    Error_Handler();
  }
}

void HAL_TIM_PeriodElapsedCallback(TIM_HandleTypeDef *htim)
{
  if (htim->Instance == TIM6) {
    HAL_IncTick();
  }
}

void Error_Handler(void)
{
}

/************************ (C) COPYRIGHT STMicroelectronics *****END OF FILE****/
